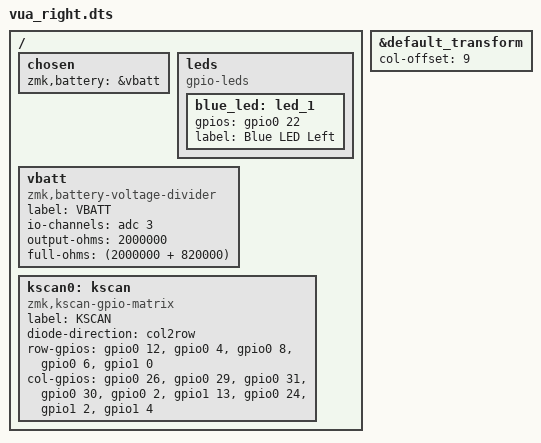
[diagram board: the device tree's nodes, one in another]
/*
*
* Copyright (c) 2023 Deemen17
* SPDX-License-Identifier: MIT
*
*/

#include "vua.dtsi"
#include <dt-bindings/led/led.h>

/ {
    chosen {
        zmk,battery = &vbatt;
    };
};

/{
    leds {
        compatible = "gpio-leds";
        blue_led: led_1 {
            gpios = <&gpio0 22 GPIO_ACTIVE_HIGH>;
            label = "Blue LED Left";
        };
    };

    vbatt: vbatt {
        compatible = "zmk,battery-voltage-divider";
        label = "VBATT";
        io-channels = <&adc 3>;
		output-ohms = <2000000>;
		full-ohms = <(2000000 + 820000)>;
    };

    kscan0: kscan {
        compatible = "zmk,kscan-gpio-matrix";
        label = "KSCAN";

        diode-direction = "col2row";

        row-gpios
            = <&gpio0 12 (GPIO_ACTIVE_HIGH | GPIO_PULL_DOWN)>
            , <&gpio0 4  (GPIO_ACTIVE_HIGH | GPIO_PULL_DOWN)>
            , <&gpio0 8  (GPIO_ACTIVE_HIGH | GPIO_PULL_DOWN)>
            , <&gpio0 6  (GPIO_ACTIVE_HIGH | GPIO_PULL_DOWN)>
            , <&gpio1 0  (GPIO_ACTIVE_HIGH | GPIO_PULL_DOWN)>
            ;
            
        col-gpios
            = <&gpio0 26 GPIO_ACTIVE_HIGH>
            , <&gpio0 29 GPIO_ACTIVE_HIGH>
            , <&gpio0 31 GPIO_ACTIVE_HIGH>
            , <&gpio0 30 GPIO_ACTIVE_HIGH>
            , <&gpio0 2  GPIO_ACTIVE_HIGH>
            , <&gpio1 13 GPIO_ACTIVE_HIGH>
            , <&gpio0 24 GPIO_ACTIVE_HIGH>
            , <&gpio1 2  GPIO_ACTIVE_HIGH>
            , <&gpio1 4  GPIO_ACTIVE_HIGH>
            ;
    };

};   

&default_transform {
    col-offset = <9>;
};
